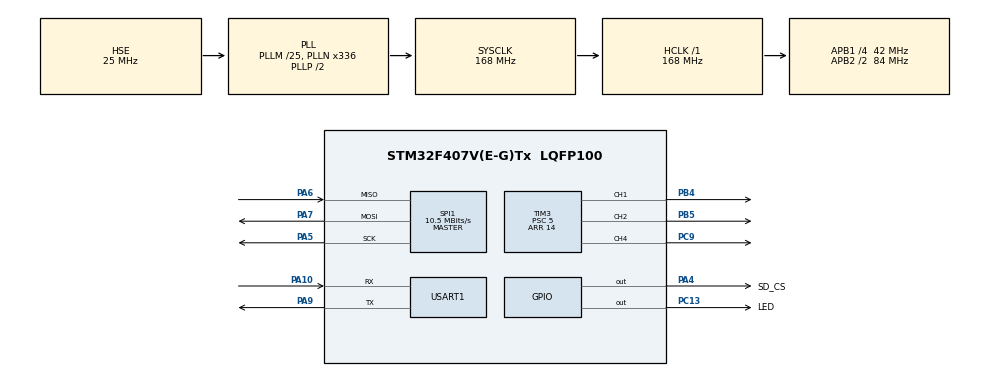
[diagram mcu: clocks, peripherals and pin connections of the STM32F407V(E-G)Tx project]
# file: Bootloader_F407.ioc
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Dma.Request0=TIM3_CH4/UP
Dma.Request1=TIM3_CH1/TRIG
Dma.Request2=TIM3_CH2
Dma.TIM3_CH1/TRIG.1.Direction=DMA_MEMORY_TO_PERIPH
Dma.TIM3_CH1/TRIG.1.FIFOMode=DMA_FIFOMODE_DISABLE
Dma.TIM3_CH1/TRIG.1.Instance=DMA1_Stream4
Dma.TIM3_CH1/TRIG.1.MemDataAlignment=DMA_MDATAALIGN_HALFWORD
Dma.TIM3_CH1/TRIG.1.MemInc=DMA_MINC_ENABLE
Dma.TIM3_CH1/TRIG.1.Mode=DMA_NORMAL
Dma.TIM3_CH1/TRIG.1.PeriphDataAlignment=DMA_PDATAALIGN_HALFWORD
Dma.TIM3_CH1/TRIG.1.PeriphInc=DMA_PINC_DISABLE
Dma.TIM3_CH1/TRIG.1.Priority=DMA_PRIORITY_LOW
Dma.TIM3_CH2.2.Direction=DMA_MEMORY_TO_PERIPH
Dma.TIM3_CH2.2.FIFOMode=DMA_FIFOMODE_DISABLE
Dma.TIM3_CH2.2.Instance=DMA1_Stream5
Dma.TIM3_CH2.2.MemDataAlignment=DMA_MDATAALIGN_HALFWORD
Dma.TIM3_CH2.2.MemInc=DMA_MINC_ENABLE
Dma.TIM3_CH2.2.Mode=DMA_NORMAL
Dma.TIM3_CH2.2.PeriphDataAlignment=DMA_PDATAALIGN_HALFWORD
Dma.TIM3_CH2.2.PeriphInc=DMA_PINC_DISABLE
Dma.TIM3_CH2.2.Priority=DMA_PRIORITY_LOW
Dma.TIM3_CH4/UP.0.Direction=DMA_MEMORY_TO_PERIPH
Dma.TIM3_CH4/UP.0.FIFOMode=DMA_FIFOMODE_DISABLE
Dma.TIM3_CH4/UP.0.Instance=DMA1_Stream2
Dma.TIM3_CH4/UP.0.MemDataAlignment=DMA_MDATAALIGN_HALFWORD
Dma.TIM3_CH4/UP.0.MemInc=DMA_MINC_ENABLE
Dma.TIM3_CH4/UP.0.Mode=DMA_NORMAL
Dma.TIM3_CH4/UP.0.PeriphDataAlignment=DMA_PDATAALIGN_HALFWORD
Dma.TIM3_CH4/UP.0.PeriphInc=DMA_PINC_DISABLE
Dma.TIM3_CH4/UP.0.Priority=DMA_PRIORITY_LOW
FATFS._CODE_PAGE=936
Mcu.Family=STM32F4
Mcu.Name=STM32F407V(E-G)Tx
Mcu.Package=LQFP100
NVIC.DMA1_Stream2_IRQn=true\:0\:0\:false\:false\:true\:false\:true\:true
NVIC.DMA1_Stream4_IRQn=true\:0\:0\:false\:false\:true\:false\:true\:true
NVIC.DMA1_Stream5_IRQn=true\:0\:0\:false\:false\:true\:false\:true\:true
NVIC.PriorityGroup=NVIC_PRIORITYGROUP_4
PA10.Mode=Asynchronous
PA10.Signal=USART1_RX
PA13.Mode=Serial_Wire
PA13.Signal=SYS_JTMS-SWDIO
PA14.Mode=Serial_Wire
PA14.Signal=SYS_JTCK-SWCLK
PA4.GPIO_Label=SD_CS
PA4.GPIO_Speed=GPIO_SPEED_FREQ_LOW
PA4.Signal=GPIO_Output
PA5.Mode=Full_Duplex_Master
PA5.Signal=SPI1_SCK
PA6.Mode=Full_Duplex_Master
PA6.Signal=SPI1_MISO
PA7.Mode=Full_Duplex_Master
PA7.Signal=SPI1_MOSI
PA9.Mode=Asynchronous
PA9.Signal=USART1_TX
PB4.Signal=S_TIM3_CH1
PB5.Signal=S_TIM3_CH2
PC13-ANTI_TAMP.GPIO_Label=LED
PC13-ANTI_TAMP.Signal=GPIO_Output
PC9.Signal=S_TIM3_CH4
PH0-OSC_IN.Mode=HSE-External-Oscillator
PH0-OSC_IN.Signal=RCC_OSC_IN
PH1-OSC_OUT.Mode=HSE-External-Oscillator
PH1-OSC_OUT.Signal=RCC_OSC_OUT
ProjectManager.HeapSize=0x1000
ProjectManager.StackSize=0x1000
ProjectManager.TargetToolchain=MDK-ARM V5.32
RCC.48MHZClocksFreq_Value=84000000
RCC.AHBFreq_Value=168000000
RCC.APB1CLKDivider=RCC_HCLK_DIV4
RCC.APB1Freq_Value=42000000
RCC.APB1TimFreq_Value=84000000
RCC.APB2CLKDivider=RCC_HCLK_DIV2
RCC.APB2Freq_Value=84000000
RCC.APB2TimFreq_Value=168000000
RCC.CortexFreq_Value=168000000
RCC.HCLKFreq_Value=168000000
RCC.HSE_Timout=1500
RCC.HSE_VALUE=25000000
RCC.HSI_VALUE=16000000
RCC.LSE_VALUE=32768
RCC.PLLM=25
RCC.PLLN=336
RCC.PLLSourceVirtual=RCC_PLLSOURCE_HSE
RCC.SYSCLKFreq_VALUE=168000000
RCC.SYSCLKSource=RCC_SYSCLKSOURCE_PLLCLK
RCC.VCOOutputFreq_Value=336000000
SH.S_TIM3_CH1.0=TIM3_CH1,PWM Generation1 CH1
SH.S_TIM3_CH2.0=TIM3_CH2,PWM Generation2 CH2
SH.S_TIM3_CH4.0=TIM3_CH4,PWM Generation4 CH4
SPI1.BaudRatePrescaler=SPI_BAUDRATEPRESCALER_8
SPI1.CalculateBaudRate=10.5 MBits/s
SPI1.Direction=SPI_DIRECTION_2LINES
SPI1.Mode=SPI_MODE_MASTER
SPI1.VirtualType=VM_MASTER
TIM3.AutoReloadPreload=TIM_AUTORELOAD_PRELOAD_ENABLE
TIM3.Channel-PWM\ Generation1\ CH1=TIM_CHANNEL_1
TIM3.Channel-PWM\ Generation2\ CH2=TIM_CHANNEL_2
TIM3.Channel-PWM\ Generation4\ CH4=TIM_CHANNEL_4
TIM3.Period=14
TIM3.Prescaler=5
USART1.VirtualMode=VM_ASYNC
VP_FATFS_VS_Generic.Mode=User_defined
VP_TIM3_VS_ClockSourceINT.Mode=Internal
board=custom

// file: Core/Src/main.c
/* USER CODE BEGIN Header */
/**
  ******************************************************************************
  * @file           : main.c
  * @brief          : Main program body
  ******************************************************************************
  * @attention
  *
  * Copyright (c) 2025 STMicroelectronics.
  * All rights reserved.
  *
  * This software is licensed under terms that can be found in the LICENSE file
  * in the root directory of this software component.
  * If no LICENSE file comes with this software, it is provided AS-IS.
  *
  ******************************************************************************
  */
/* USER CODE END Header */
#include "main.h"
#include "dma.h"
#include "fatfs.h"
#include "spi.h"
#include "tim.h"
#include "usart.h"
#include "gpio.h"

/* USER CODE BEGIN Includes */
#include "fatfs_sd.h"
#include "app_sd.h"
#include "app_bootloader.h"
/* USER CODE END Includes */

void SystemClock_Config(void);

int main(void)
{

  /* MCU Configuration--------------------------------------------------------*/

  /* Reset of all peripherals, Initializes the Flash interface and the Systick. */
  HAL_Init();

  /* Configure the system clock */
  SystemClock_Config();

  /* Initialize all configured peripherals */
  MX_GPIO_Init();
  MX_DMA_Init();
  MX_SPI1_Init();
  MX_FATFS_Init();
  MX_USART1_UART_Init();
  MX_TIM3_Init();
  /* USER CODE BEGIN 2 */
  HAL_Delay(10);
  App_Bootloader();
  /* USER CODE END 2 */

  /* Infinite loop */
  while (1)
  {

  }
}

void SystemClock_Config(void)
{
  RCC_OscInitTypeDef RCC_OscInitStruct = {0};
  RCC_ClkInitTypeDef RCC_ClkInitStruct = {0};

  /** Configure the main internal regulator output voltage
  */
  __HAL_RCC_PWR_CLK_ENABLE();
  __HAL_PWR_VOLTAGESCALING_CONFIG(PWR_REGULATOR_VOLTAGE_SCALE1);

  /** Initializes the RCC Oscillators according to the specified parameters
  * in the RCC_OscInitTypeDef structure.
  */
  RCC_OscInitStruct.OscillatorType = RCC_OSCILLATORTYPE_HSE;
  RCC_OscInitStruct.HSEState = RCC_HSE_ON;
  RCC_OscInitStruct.PLL.PLLState = RCC_PLL_ON;
  RCC_OscInitStruct.PLL.PLLSource = RCC_PLLSOURCE_HSE;
  RCC_OscInitStruct.PLL.PLLM = 25;
  RCC_OscInitStruct.PLL.PLLN = 336;
  RCC_OscInitStruct.PLL.PLLP = RCC_PLLP_DIV2;
  RCC_OscInitStruct.PLL.PLLQ = 4;
  if (HAL_RCC_OscConfig(&RCC_OscInitStruct) != HAL_OK)
  {
    Error_Handler();
  }

  /** Initializes the CPU, AHB and APB buses clocks
  */
  RCC_ClkInitStruct.ClockType = RCC_CLOCKTYPE_HCLK|RCC_CLOCKTYPE_SYSCLK
                              |RCC_CLOCKTYPE_PCLK1|RCC_CLOCKTYPE_PCLK2;
  RCC_ClkInitStruct.SYSCLKSource = RCC_SYSCLKSOURCE_PLLCLK;
  RCC_ClkInitStruct.AHBCLKDivider = RCC_SYSCLK_DIV1;
  RCC_ClkInitStruct.APB1CLKDivider = RCC_HCLK_DIV4;
  RCC_ClkInitStruct.APB2CLKDivider = RCC_HCLK_DIV2;

  if (HAL_RCC_ClockConfig(&RCC_ClkInitStruct, FLASH_LATENCY_5) != HAL_OK)
  {
    Error_Handler();
  }
}

void Error_Handler(void)
{
  __disable_irq();
  while (1)
  {
  }
}
